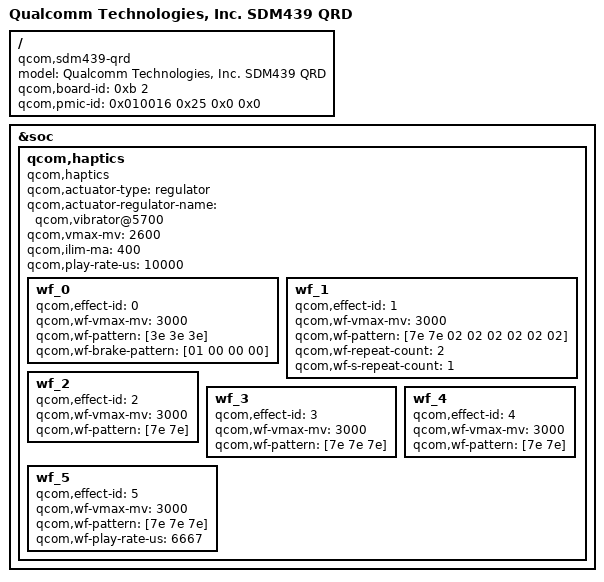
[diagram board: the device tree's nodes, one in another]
/*
 * Copyright (c) 2018, The Linux Foundation. All rights reserved.
 *
 * This program is free software; you can redistribute it and/or modify
 * it under the terms of the GNU General Public License version 2 and
 * only version 2 as published by the Free Software Foundation.
 *
 * This program is distributed in the hope that it will be useful,
 * but WITHOUT ANY WARRANTY; without even the implied warranty of
 * MERCHANTABILITY or FITNESS FOR A PARTICULAR PURPOSE.  See the
 * GNU General Public License for more details.
 */

/dts-v1/;

#include "sdm439.dtsi"
#include "sdm439-qrd.dtsi"

/ {
	model = "Qualcomm Technologies, Inc. SDM439 QRD";
	compatible = "qcom,sdm439-qrd", "qcom,sdm439", "qcom,qrd";
	qcom,board-id = <0xb 2>;
	qcom,pmic-id = <0x010016 0x25 0x0 0x0>;
};

&soc {
	qcom,haptics {
		compatible = "qcom,haptics";
		/* vib_regulator-supply = <&>; */
		qcom,actuator-type = "regulator";
		qcom,actuator-regulator-name = "qcom,vibrator@5700";
		qcom,vmax-mv = <2600>;
		qcom,ilim-ma = <400>;
		qcom,play-rate-us = <10000>;
		wf_0 {
			/* CLICK */
			qcom,effect-id = <0>;
			qcom,wf-vmax-mv = <3000>;
			qcom,wf-pattern = [3e 3e 3e];
			qcom,wf-brake-pattern = [01 00 00 00];
		};
		wf_1 {
			/* DOUBLE CLICK */
			qcom,effect-id = <1>;
			qcom,wf-vmax-mv = <3000>;
			qcom,wf-pattern = [7e 7e 02 02 02 02 02 02];
			qcom,wf-repeat-count = <2>;
			qcom,wf-s-repeat-count = <1>;
		};
		wf_2 {
			/* TICK */
			qcom,effect-id = <2>;
			qcom,wf-vmax-mv = <3000>;
			qcom,wf-pattern = [7e 7e];
		};
		wf_3 {
			/* THUD */
			qcom,effect-id = <3>;
			qcom,wf-vmax-mv = <3000>;
			qcom,wf-pattern = [7e 7e 7e];
		};
		wf_4 {
			/* POP */
			qcom,effect-id = <4>;
			qcom,wf-vmax-mv = <3000>;
			qcom,wf-pattern = [7e 7e];
		};
		wf_5 {
			/* HEAVY CLICK */
			qcom,effect-id = <5>;
			qcom,wf-vmax-mv = <3000>;
			qcom,wf-pattern = [7e 7e 7e];
			qcom,wf-play-rate-us = <6667>;
		};
	};
};
